AUTOSAR XML (schema 00049)
package /ComponentTypes
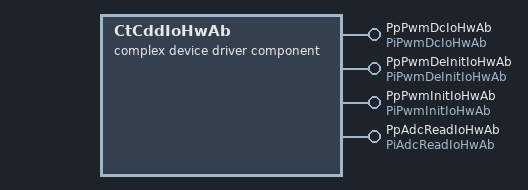
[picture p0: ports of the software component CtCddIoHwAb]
  complex device driver sw component type CtCddIoHwAb
    4 x provide port:
      PpPwmDcIoHwAb: server-com-spec{operation=SetDutyCycle, queue-length=1}, provided-interface=PiPwmDcIoHwAb
      PpPwmDeInitIoHwAb: server-com-spec{operation=Pwm_DeInit, queue-length=1}, provided-interface=PiPwmDeInitIoHwAb
      PpPwmInitIoHwAb: server-com-spec{operation=Pwm_Init, queue-length=1}, provided-interface=PiPwmInitIoHwAb
      PpAdcReadIoHwAb: server-com-spec{operation=ReadGroup, queue-length=1}, provided-interface=PiAdcReadIoHwAb
    behavior CtCddIoHwAb_InternalBehavior
      operation invoked event OIT_RCtCddIoHwAb_PpPwmDcIoHwAb_SetDutyCycle_PpPwmDcIoHwAb_SetDutyCycle: start-on-event=RCtCddIoHwAb_PpPwmDcIoHwAb_SetDutyCycle, operation=PpPwmDcIoHwAb.SetDutyCycle
      operation invoked event OIT_RCtCddIoHwAb_PpPwmDeInitIoHwAb_Pwm_DeInit_PpPwmDeInitIoHwAb_Pwm_DeInit: start-on-event=RCtCddIoHwAb_PpPwmDeInitIoHwAb_Pwm_DeInit, operation=PpPwmDeInitIoHwAb.Pwm_DeInit
      operation invoked event OIT_RCtCddIoHwAb_PpPwmInitIoHwAb_Pwm_Init_PpPwmInitIoHwAb_Pwm_Init: start-on-event=RCtCddIoHwAb_PpPwmInitIoHwAb_Pwm_Init, operation=PpPwmInitIoHwAb.Pwm_Init
      init event CtCddIoHwAb_InitEvent: start-on-event=RCtCddIoHwAb_Init
      operation invoked event OIT_RCtCddIoHwAb_PpAdcReadGroup_ReadGroup_PpAdcReadGroup_ReadGroup: start-on-event=RCtCddIoHwAb_PpAdcReadIoHwAb_ReadGroup, operation=PpAdcReadIoHwAb.ReadGroup
      5 x runnable:
        RCtCddIoHwAb_PpPwmDcIoHwAb_SetDutyCycle
        RCtCddIoHwAb_PpPwmDeInitIoHwAb_Pwm_DeInit
        RCtCddIoHwAb_PpPwmInitIoHwAb_Pwm_Init
        RCtCddIoHwAb_Init
        RCtCddIoHwAb_PpAdcReadIoHwAb_ReadGroup: can-be-invoked-concurrently=true
  swc implementation CtCddIoHwAb_Implementation: behavior=CtCddIoHwAb_InternalBehavior
